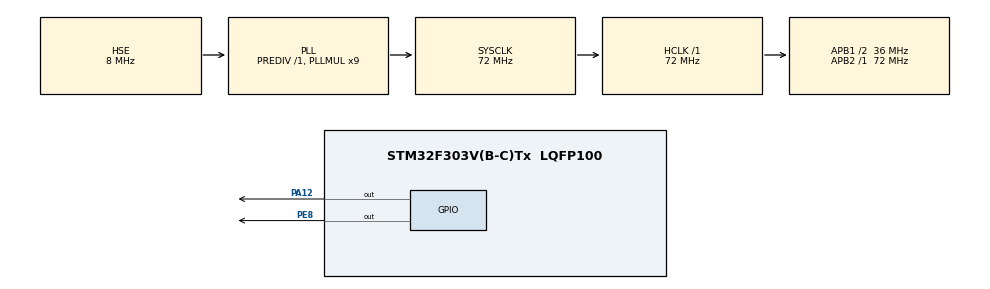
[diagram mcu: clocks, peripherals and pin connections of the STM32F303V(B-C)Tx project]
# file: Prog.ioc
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Mcu.Family=STM32F3
Mcu.Name=STM32F303V(B-C)Tx
Mcu.Package=LQFP100
NVIC.PriorityGroup=NVIC_PRIORITYGROUP_0
PA12.PinState=GPIO_PIN_RESET
PA12.Signal=GPIO_Output
PE8.Signal=GPIO_Output
PF0-OSC_IN.GPIO_Label=OSC_IN
PF0-OSC_IN.Mode=HSE-External-Clock-Source
PF0-OSC_IN.Signal=RCC_OSC_IN
ProjectManager.HeapSize=0x200
ProjectManager.StackSize=0x400
ProjectManager.TargetToolchain=STM32CubeIDE
RCC.AHBFreq_Value=72000000
RCC.APB1CLKDivider=RCC_HCLK_DIV2
RCC.APB1Freq_Value=36000000
RCC.APB1TimFreq_Value=72000000
RCC.APB2Freq_Value=72000000
RCC.APB2TimFreq_Value=72000000
RCC.CortexFreq_Value=72000000
RCC.HCLKFreq_Value=72000000
RCC.HSE_VALUE=8000000
RCC.HSI_VALUE=8000000
RCC.LSE_VALUE=32768
RCC.PLLMUL=RCC_PLL_MUL9
RCC.PLLSourceVirtual=RCC_PLLSOURCE_HSE
RCC.SYSCLKFreq_VALUE=72000000
RCC.SYSCLKSourceVirtual=RCC_SYSCLKSOURCE_PLLCLK
RCC.USBFreq_Value=72000000
board=STM32F3DISCOVERY

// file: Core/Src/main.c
/* USER CODE BEGIN Header */
/**
  ******************************************************************************
  * @file           : main.c
  * @brief          : Main program body
  ******************************************************************************
  * @attention
  *
  * <h2><center>&copy; Copyright (c) 2020 STMicroelectronics.
  * All rights reserved.</center></h2>
  *
  * This software component is licensed by ST under BSD 3-Clause license,
  * the "License"; You may not use this file except in compliance with the
  * License. You may obtain a copy of the License at:
  *                        opensource.org/licenses/BSD-3-Clause
  *
  ******************************************************************************
  */
/* USER CODE END Header */
#include "main.h"

/* USER CODE BEGIN Includes */
#include "header.h"
/* USER CODE END Includes */

void SystemClock_Config(void);
static void MX_GPIO_Init(void);

/* USER CODE BEGIN 0 */
/**
  * @brief  Vector base address configuration. It should no longer be at the start of
  *         flash memory but moved forward because the first part of flash is
  *         reserved for the bootloader. Note that this is already done by the
  *         bootloader before starting this program. Unfortunately, function
  *         SystemInit() overwrites this change again.
  * @return none.
  */
static void VectorBase_Config(void)
{
  /* The constant array with vectors of the vector table is declared externally in the
   * c-startup code.
   */
  extern const unsigned long g_pfnVectors[];

  /* Remap the vector table to where the vector table is located for this program. */
  SCB->VTOR = (unsigned long)&g_pfnVectors[0];
}
/* USER CODE END 0 */

int main(void)
{
  /* USER CODE BEGIN 1 */
  /* The STM32F3-Discovery board has a pull-up on the USB_DP line, which is always
   * enabled by default. If the USB USER cable is connected (for example after a
   * firmware update with the bootloader), this pull-up causes the USB host to try
   * and enumerate the USB device. This enumeration will fail if this application itself
   * does not make use of the USB peripheral. This failed enumeration is not a problem
   * for this application, but will cause the bootloader to not enumerate properly after
   * starting it via a system reset.
   * To prevent enumeration by the USB host, the USB device needs to stay in a
   * disconnected state, which is done by configuring the USB_DP line as a digital
   * output and setting it to logic low.
   */
  /* Configure the vector table base address. */
  VectorBase_Config();
  /* USER CODE END 1 */

  /* MCU Configuration--------------------------------------------------------*/

  /* Reset of all peripherals, Initializes the Flash interface and the Systick. */
  HAL_Init();

  /* Configure the system clock */
  SystemClock_Config();

  /* Initialize all configured peripherals */
  MX_GPIO_Init();
  /* USER CODE BEGIN 2 */
  /* Initialize the user program application. */
  AppInit();
  /* USER CODE END 2 */

  /* Infinite loop */
  /* USER CODE BEGIN WHILE */
  while (1)
  {
    /* Run the user program application. */
    AppTask();
    /* USER CODE END WHILE */

  }
}

void SystemClock_Config(void)
{
  RCC_OscInitTypeDef RCC_OscInitStruct = {0};
  RCC_ClkInitTypeDef RCC_ClkInitStruct = {0};

  /** Initializes the RCC Oscillators according to the specified parameters
  * in the RCC_OscInitTypeDef structure.
  */
  RCC_OscInitStruct.OscillatorType = RCC_OSCILLATORTYPE_HSE;
  RCC_OscInitStruct.HSEState = RCC_HSE_BYPASS;
  RCC_OscInitStruct.HSEPredivValue = RCC_HSE_PREDIV_DIV1;
  RCC_OscInitStruct.HSIState = RCC_HSI_ON;
  RCC_OscInitStruct.PLL.PLLState = RCC_PLL_ON;
  RCC_OscInitStruct.PLL.PLLSource = RCC_PLLSOURCE_HSE;
  RCC_OscInitStruct.PLL.PLLMUL = RCC_PLL_MUL9;
  if (HAL_RCC_OscConfig(&RCC_OscInitStruct) != HAL_OK)
  {
    Error_Handler();
  }
  /** Initializes the CPU, AHB and APB buses clocks
  */
  RCC_ClkInitStruct.ClockType = RCC_CLOCKTYPE_HCLK|RCC_CLOCKTYPE_SYSCLK
                              |RCC_CLOCKTYPE_PCLK1|RCC_CLOCKTYPE_PCLK2;
  RCC_ClkInitStruct.SYSCLKSource = RCC_SYSCLKSOURCE_PLLCLK;
  RCC_ClkInitStruct.AHBCLKDivider = RCC_SYSCLK_DIV1;
  RCC_ClkInitStruct.APB1CLKDivider = RCC_HCLK_DIV2;
  RCC_ClkInitStruct.APB2CLKDivider = RCC_HCLK_DIV1;

  if (HAL_RCC_ClockConfig(&RCC_ClkInitStruct, FLASH_LATENCY_2) != HAL_OK)
  {
    Error_Handler();
  }
}

static void MX_GPIO_Init(void)
{
  GPIO_InitTypeDef GPIO_InitStruct = {0};

  /* GPIO Ports Clock Enable */
  __HAL_RCC_GPIOF_CLK_ENABLE();
  __HAL_RCC_GPIOE_CLK_ENABLE();
  __HAL_RCC_GPIOA_CLK_ENABLE();

  /*Configure GPIO pin Output Level */
  HAL_GPIO_WritePin(GPIOE, GPIO_PIN_8, GPIO_PIN_RESET);

  /*Configure GPIO pin Output Level */
  HAL_GPIO_WritePin(GPIOA, GPIO_PIN_12, GPIO_PIN_RESET);

  /*Configure GPIO pin : PE8 */
  GPIO_InitStruct.Pin = GPIO_PIN_8;
  GPIO_InitStruct.Mode = GPIO_MODE_OUTPUT_PP;
  GPIO_InitStruct.Pull = GPIO_NOPULL;
  GPIO_InitStruct.Speed = GPIO_SPEED_FREQ_LOW;
  HAL_GPIO_Init(GPIOE, &GPIO_InitStruct);

  /*Configure GPIO pin : PA12 */
  GPIO_InitStruct.Pin = GPIO_PIN_12;
  GPIO_InitStruct.Mode = GPIO_MODE_OUTPUT_PP;
  GPIO_InitStruct.Pull = GPIO_NOPULL;
  GPIO_InitStruct.Speed = GPIO_SPEED_FREQ_LOW;
  HAL_GPIO_Init(GPIOA, &GPIO_InitStruct);

}

void Error_Handler(void)
{
}

/************************ (C) COPYRIGHT STMicroelectronics *****END OF FILE****/
